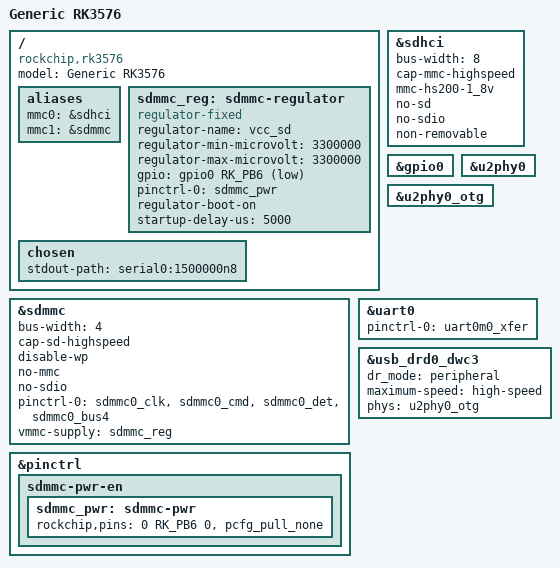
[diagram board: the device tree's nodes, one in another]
// SPDX-License-Identifier: (GPL-2.0+ OR MIT)
/*
 * Minimal generic DT for RK3576 with eMMC, SD-card and USB OTG enabled
 */

/dts-v1/;

#include <dt-bindings/gpio/gpio.h>
#include "rk3576.dtsi"

/ {
	model = "Generic RK3576";
	compatible = "rockchip,rk3576";

	aliases {
		mmc0 = &sdhci;
		mmc1 = &sdmmc;
	};

	sdmmc_reg: sdmmc-regulator {
		compatible = "regulator-fixed";
		regulator-name = "vcc_sd";
		regulator-min-microvolt = <3300000>;
		regulator-max-microvolt = <3300000>;
		gpio = <&gpio0 RK_PB6 GPIO_ACTIVE_LOW>;
		pinctrl-names = "default";
		pinctrl-0 = <&sdmmc_pwr>;
		regulator-boot-on;
		startup-delay-us = <5000>;
		bootph-pre-ram;
	};

	chosen {
		stdout-path = "serial0:1500000n8";
	};
};

&sdhci {
	bus-width = <8>;
	cap-mmc-highspeed;
	mmc-hs200-1_8v;
	no-sd;
	no-sdio;
	non-removable;
	status = "okay";
};

&sdmmc {
	bootph-pre-ram;
	bus-width = <4>;
	cap-sd-highspeed;
	disable-wp;
	no-mmc;
	no-sdio;
	pinctrl-0 = <&sdmmc0_clk &sdmmc0_cmd &sdmmc0_det &sdmmc0_bus4>;
	vmmc-supply = <&sdmmc_reg>;
	status = "okay";
};

&gpio0 {
	bootph-pre-ram;
};

&pinctrl {
	sdmmc-pwr-en {
		sdmmc_pwr: sdmmc-pwr {
			rockchip,pins = <0 RK_PB6 0 &pcfg_pull_none>;
			bootph-pre-ram;
		};
	};
};

&u2phy0 {
	status = "okay";
};

&u2phy0_otg {
	status = "okay";
};

&uart0 {
	pinctrl-0 = <&uart0m0_xfer>;
	status = "okay";
};

&usb_drd0_dwc3 {
	dr_mode = "peripheral";
	maximum-speed = "high-speed";
	phys = <&u2phy0_otg>;
	phy-names = "usb2-phy";
	status = "okay";
};
